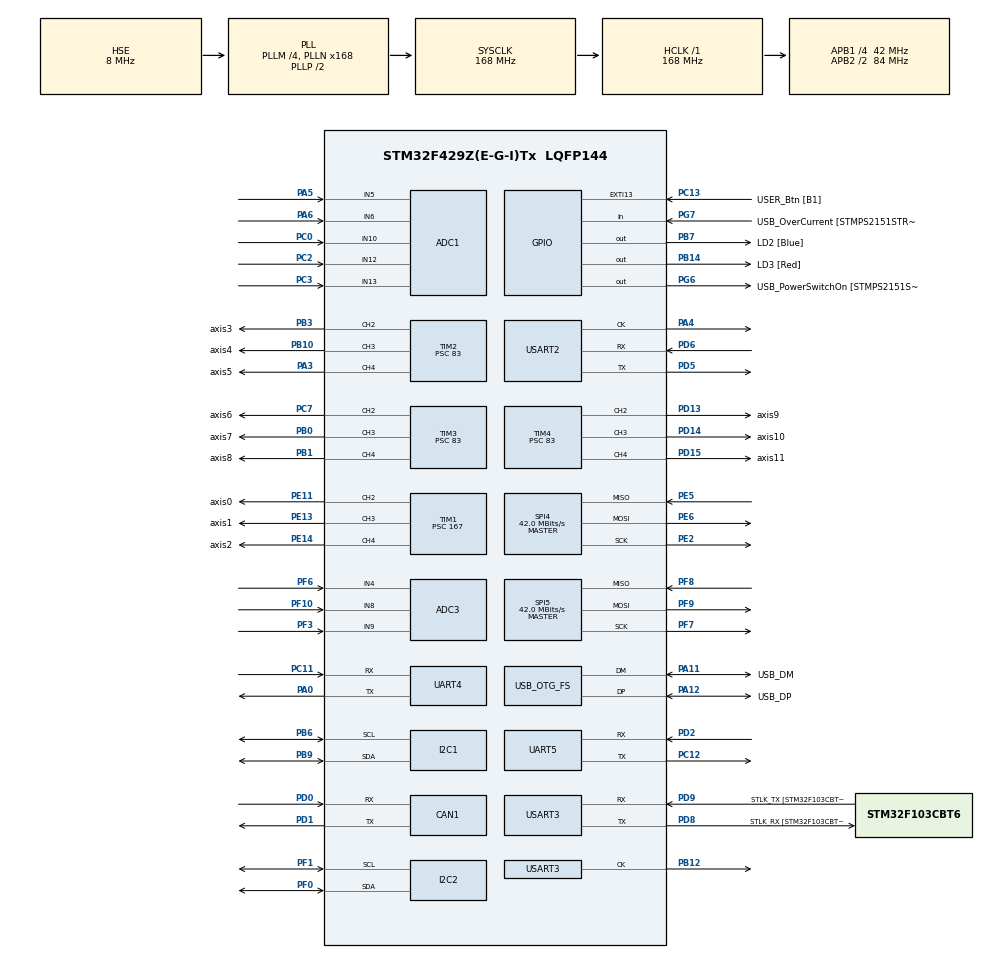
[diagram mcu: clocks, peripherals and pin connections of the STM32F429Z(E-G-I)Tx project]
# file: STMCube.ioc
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ADC1.Channel-0\#ChannelRegularConversion=ADC_CHANNEL_10
ADC1.NbrOfConversionFlag=1
ADC1.Rank-0\#ChannelRegularConversion=1
ADC1.SamplingTime-0\#ChannelRegularConversion=ADC_SAMPLETIME_3CYCLES
ADC1.master=1
ADC2.Channel-0\#ChannelRegularConversion=ADC_CHANNEL_10
ADC2.NbrOfConversionFlag=1
ADC2.Rank-0\#ChannelRegularConversion=1
ADC2.SamplingTime-0\#ChannelRegularConversion=ADC_SAMPLETIME_3CYCLES
ADC3.Channel-0\#ChannelRegularConversion=ADC_CHANNEL_4
ADC3.NbrOfConversionFlag=1
ADC3.Rank-0\#ChannelRegularConversion=1
ADC3.SamplingTime-0\#ChannelRegularConversion=ADC_SAMPLETIME_3CYCLES
CAN1.BS1=CAN_BS1_1TQ
CAN1.BS2=CAN_BS2_1TQ
CAN1.CalculateTimeBit=1142
CAN1.CalculateTimeQuantum=380.95238095238096
Dma.Request0=TIM1_CH1
Dma.Request1=TIM2_CH1
Dma.Request2=TIM3_CH1/TRIG
Dma.Request3=TIM4_CH1
Dma.TIM1_CH1.0.Direction=DMA_MEMORY_TO_PERIPH
Dma.TIM1_CH1.0.FIFOMode=DMA_FIFOMODE_DISABLE
Dma.TIM1_CH1.0.Instance=DMA2_Stream1
Dma.TIM1_CH1.0.MemDataAlignment=DMA_MDATAALIGN_HALFWORD
Dma.TIM1_CH1.0.MemInc=DMA_MINC_ENABLE
Dma.TIM1_CH1.0.Mode=DMA_NORMAL
Dma.TIM1_CH1.0.PeriphDataAlignment=DMA_PDATAALIGN_HALFWORD
Dma.TIM1_CH1.0.PeriphInc=DMA_PINC_DISABLE
Dma.TIM1_CH1.0.Priority=DMA_PRIORITY_HIGH
Dma.TIM2_CH1.1.Direction=DMA_MEMORY_TO_PERIPH
Dma.TIM2_CH1.1.FIFOMode=DMA_FIFOMODE_DISABLE
Dma.TIM2_CH1.1.Instance=DMA1_Stream5
Dma.TIM2_CH1.1.MemDataAlignment=DMA_MDATAALIGN_WORD
Dma.TIM2_CH1.1.MemInc=DMA_MINC_ENABLE
Dma.TIM2_CH1.1.Mode=DMA_NORMAL
Dma.TIM2_CH1.1.PeriphDataAlignment=DMA_PDATAALIGN_WORD
Dma.TIM2_CH1.1.PeriphInc=DMA_PINC_DISABLE
Dma.TIM2_CH1.1.Priority=DMA_PRIORITY_HIGH
Dma.TIM3_CH1/TRIG.2.Direction=DMA_MEMORY_TO_PERIPH
Dma.TIM3_CH1/TRIG.2.FIFOMode=DMA_FIFOMODE_DISABLE
Dma.TIM3_CH1/TRIG.2.Instance=DMA1_Stream4
Dma.TIM3_CH1/TRIG.2.MemDataAlignment=DMA_MDATAALIGN_HALFWORD
Dma.TIM3_CH1/TRIG.2.MemInc=DMA_MINC_ENABLE
Dma.TIM3_CH1/TRIG.2.Mode=DMA_NORMAL
Dma.TIM3_CH1/TRIG.2.PeriphDataAlignment=DMA_PDATAALIGN_HALFWORD
Dma.TIM3_CH1/TRIG.2.PeriphInc=DMA_PINC_DISABLE
Dma.TIM3_CH1/TRIG.2.Priority=DMA_PRIORITY_HIGH
Dma.TIM4_CH1.3.Direction=DMA_MEMORY_TO_PERIPH
Dma.TIM4_CH1.3.FIFOMode=DMA_FIFOMODE_DISABLE
Dma.TIM4_CH1.3.Instance=DMA1_Stream0
Dma.TIM4_CH1.3.MemDataAlignment=DMA_MDATAALIGN_HALFWORD
Dma.TIM4_CH1.3.MemInc=DMA_MINC_ENABLE
Dma.TIM4_CH1.3.Mode=DMA_NORMAL
Dma.TIM4_CH1.3.PeriphDataAlignment=DMA_PDATAALIGN_HALFWORD
Dma.TIM4_CH1.3.PeriphInc=DMA_PINC_DISABLE
Dma.TIM4_CH1.3.Priority=DMA_PRIORITY_HIGH
FREERTOS.Tasks01=defaultTask,0,128,StartDefaultTask,Default,NULL
FREERTOS.configENABLE_BACKWARD_COMPATIBILITY=0
FREERTOS.configTOTAL_HEAP_SIZE=65536
FREERTOS.configUSE_COUNTING_SEMAPHORES=1
Mcu.Family=STM32F4
Mcu.Name=STM32F429Z(E-G-I)Tx
Mcu.Package=LQFP144
NVIC.DMA1_Stream0_IRQn=true\:5\:0\:false\:false\:true\:true\:false
NVIC.DMA1_Stream4_IRQn=true\:5\:0\:false\:false\:true\:true\:false
NVIC.DMA1_Stream5_IRQn=true\:5\:0\:false\:false\:true\:true\:false
NVIC.DMA2_Stream1_IRQn=true\:5\:0\:false\:false\:true\:true\:false
NVIC.OTG_FS_IRQn=true\:5\:0\:false\:false\:true\:true\:false
NVIC.PriorityGroup=NVIC_PRIORITYGROUP_4
NVIC.TIM8_UP_TIM13_IRQn=true\:0\:0\:false\:false\:true\:false\:false
NVIC.TimeBase=TIM8_UP_TIM13_IRQn
NVIC.TimeBaseIP=TIM13
PA0/WKUP.Mode=Asynchronous
PA0/WKUP.Signal=UART4_TX
PA1.GPIO_Label=RMII_REF_CLK [LAN8742A-CZ-TR_REFCLK0]
PA1.Signal=ETH_REF_CLK
PA10.GPIO_Label=USB_ID
PA10.Signal=USB_OTG_FS_ID
PA11.GPIO_Label=USB_DM
PA11.Mode=Device_Only
PA11.Signal=USB_OTG_FS_DM
PA12.GPIO_Label=USB_DP
PA12.Mode=Device_Only
PA12.Signal=USB_OTG_FS_DP
PA13.GPIO_Label=TMS
PA13.Mode=Serial_Wire
PA13.Signal=SYS_JTMS-SWDIO
PA14.GPIO_Label=TCK
PA14.Mode=Serial_Wire
PA14.Signal=SYS_JTCK-SWCLK
PA2.GPIO_Label=RMII_MDIO [LAN8742A-CZ-TR_MDIO]
PA2.Signal=ETH_MDIO
PA3.GPIO_Label=axis5
PA3.GPIO_Speed=GPIO_SPEED_FREQ_VERY_HIGH
PA3.Signal=S_TIM2_CH4
PA4.Mode=Synchronous
PA4.Signal=USART2_CK
PA5.Signal=ADCx_IN5
PA6.Signal=ADCx_IN6
PA7.GPIO_Label=RMII_CRS_DV [LAN8742A-CZ-TR_CRS_DV]
PA7.Signal=ETH_CRS_DV
PA8.GPIO_Label=USB_SOF [TP1]
PA8.Signal=USB_OTG_FS_SOF
PA9.GPIO_Label=USB_VBUS
PA9.Signal=USB_OTG_FS_VBUS
PB0.GPIO_Label=axis7
PB0.GPIO_Speed=GPIO_SPEED_FREQ_VERY_HIGH
PB0.Signal=S_TIM3_CH3
PB1.GPIO_Label=axis8
PB1.GPIO_Speed=GPIO_SPEED_FREQ_VERY_HIGH
PB1.Signal=S_TIM3_CH4
PB10.GPIO_Label=axis4
PB10.GPIO_Speed=GPIO_SPEED_FREQ_VERY_HIGH
PB10.Signal=S_TIM2_CH3
PB12.Mode=Synchronous
PB12.Signal=USART3_CK
PB13.GPIO_Label=RMII_TXD1 [LAN8742A-CZ-TR_TXD1]
PB13.Signal=ETH_TXD1
PB14.GPIO_Label=LD3 [Red]
PB14.Signal=GPIO_Output
PB3.GPIO_Label=axis3
PB3.GPIO_Speed=GPIO_SPEED_FREQ_VERY_HIGH
PB3.Signal=S_TIM2_CH2
PB6.Mode=I2C
PB6.Signal=I2C1_SCL
PB7.GPIO_Label=LD2 [Blue]
PB7.Signal=GPIO_Output
PB9.Mode=I2C
PB9.Signal=I2C1_SDA
PC0.Signal=ADCx_IN10
PC1.GPIO_Label=RMII_MDC [LAN8742A-CZ-TR_MDC]
PC1.Signal=ETH_MDC
PC11.Mode=Asynchronous
PC11.Signal=UART4_RX
PC12.Mode=Asynchronous
PC12.Signal=UART5_TX
PC13.GPIO_Label=USER_Btn [B1]
PC13.Signal=GPXTI13
PC14/OSC32_IN.Mode=LSE-External-Oscillator
PC14/OSC32_IN.Signal=RCC_OSC32_IN
PC15/OSC32_OUT.Mode=LSE-External-Oscillator
PC15/OSC32_OUT.Signal=RCC_OSC32_OUT
PC2.Signal=ADCx_IN12
PC3.Signal=ADCx_IN13
PC4.GPIO_Label=RMII_RXD0 [LAN8742A-CZ-TR_RXD0]
PC4.Signal=ETH_RXD0
PC5.GPIO_Label=RMII_RXD1 [LAN8742A-CZ-TR_RXD1]
PC5.Signal=ETH_RXD1
PC7.GPIO_Label=axis6
PC7.GPIO_Speed=GPIO_SPEED_FREQ_VERY_HIGH
PC7.Signal=S_TIM3_CH2
PD0.Mode=Master
PD0.Signal=CAN1_RX
PD1.Mode=Master
PD1.Signal=CAN1_TX
PD13.GPIO_Label=axis9
PD13.GPIO_Speed=GPIO_SPEED_FREQ_VERY_HIGH
PD13.Signal=S_TIM4_CH2
PD14.GPIO_Label=axis10
PD14.GPIO_Speed=GPIO_SPEED_FREQ_VERY_HIGH
PD14.Signal=S_TIM4_CH3
PD15.GPIO_Label=axis11
PD15.GPIO_Speed=GPIO_SPEED_FREQ_VERY_HIGH
PD15.Signal=S_TIM4_CH4
PD2.Mode=Asynchronous
PD2.Signal=UART5_RX
PD5.Mode=Synchronous
PD5.Signal=USART2_TX
PD6.Mode=Synchronous
PD6.Signal=USART2_RX
PD8.GPIO_Label=STLK_RX [STM32F103CBT6_PA3]
PD8.Mode=Synchronous
PD8.Signal=USART3_TX
PD9.GPIO_Label=STLK_TX [STM32F103CBT6_PA2]
PD9.Mode=Synchronous
PD9.Signal=USART3_RX
PE11.GPIO_Label=axis0
PE11.GPIO_Speed=GPIO_SPEED_FREQ_VERY_HIGH
PE11.Signal=S_TIM1_CH2
PE13.GPIO_Label=axis1
PE13.GPIO_Speed=GPIO_SPEED_FREQ_VERY_HIGH
PE13.Signal=S_TIM1_CH3
PE14.GPIO_Label=axis2
PE14.GPIO_Speed=GPIO_SPEED_FREQ_VERY_HIGH
PE14.Signal=S_TIM1_CH4
PE2.Mode=Full_Duplex_Master
PE2.Signal=SPI4_SCK
PE5.Mode=Full_Duplex_Master
PE5.Signal=SPI4_MISO
PE6.Mode=Full_Duplex_Master
PE6.Signal=SPI4_MOSI
PF0.Mode=I2C
PF0.Signal=I2C2_SDA
PF1.Mode=I2C
PF1.Signal=I2C2_SCL
PF10.Mode=IN8
PF10.Signal=ADC3_IN8
PF3.Mode=IN9
PF3.Signal=ADC3_IN9
PF6.Mode=IN4
PF6.Signal=ADC3_IN4
PF7.Mode=Full_Duplex_Master
PF7.Signal=SPI5_SCK
PF8.Mode=Full_Duplex_Master
PF8.Signal=SPI5_MISO
PF9.Mode=Full_Duplex_Master
PF9.Signal=SPI5_MOSI
PG11.GPIO_Label=RMII_TX_EN [LAN8742A-CZ-TR_TXEN]
PG11.Signal=ETH_TX_EN
PG13.GPIO_Label=RMII_TXD0 [LAN8742A-CZ-TR_TXD0]
PG13.Signal=ETH_TXD0
PG6.GPIO_Label=USB_PowerSwitchOn [STMPS2151STR_EN]
PG6.Signal=GPIO_Output
PG7.GPIO_Label=USB_OverCurrent [STMPS2151STR_FAULT]
PG7.Signal=GPIO_Input
PH0/OSC_IN.GPIO_Label=MCO [STM32F103CBT6_PA8]
PH0/OSC_IN.Mode=HSE-External-Oscillator
PH0/OSC_IN.Signal=RCC_OSC_IN
PH1/OSC_OUT.Mode=HSE-External-Oscillator
PH1/OSC_OUT.Signal=RCC_OSC_OUT
ProjectManager.HeapSize=0x200
ProjectManager.StackSize=0x400
ProjectManager.TargetToolchain=SW4STM32
RCC.48MHZClocksFreq_Value=48000000
RCC.AHBFreq_Value=168000000
RCC.APB1CLKDivider=RCC_HCLK_DIV4
RCC.APB1Freq_Value=42000000
RCC.APB1TimFreq_Value=84000000
RCC.APB2CLKDivider=RCC_HCLK_DIV2
RCC.APB2Freq_Value=84000000
RCC.APB2TimFreq_Value=168000000
RCC.CortexFreq_Value=168000000
RCC.HCLKFreq_Value=168000000
RCC.HSE_VALUE=8000000
RCC.HSI_VALUE=16000000
RCC.PLLM=4
RCC.PLLMUL=RCC_PLL_MUL9
RCC.PLLN=168
RCC.PLLQ=7
RCC.PRESCALERUSB=RCC_USBCLKSOURCE_PLL_DIV1_5
RCC.SYSCLKFreq_VALUE=168000000
RCC.SYSCLKSource=RCC_SYSCLKSOURCE_PLLCLK
RCC.SYSCLKSourceVirtual=RCC_SYSCLKSOURCE_PLLCLK
RCC.USBFreq_Value=48000000
RCC.VCOOutputFreq_Value=336000000
SH.ADCx_IN10.0=ADC1_IN10,IN10
SH.ADCx_IN10.1=ADC2_IN10,IN10
SH.ADCx_IN10.2=ADC3_IN10,IN10
SH.ADCx_IN12.0=ADC1_IN12,IN12
SH.ADCx_IN12.1=ADC2_IN12,IN12
SH.ADCx_IN12.2=ADC3_IN12,IN12
SH.ADCx_IN13.0=ADC1_IN13,IN13
SH.ADCx_IN13.1=ADC2_IN13,IN13
SH.ADCx_IN13.2=ADC3_IN13,IN13
SH.ADCx_IN5.0=ADC1_IN5,IN5
SH.ADCx_IN5.1=ADC2_IN5,IN5
SH.ADCx_IN6.0=ADC1_IN6,IN6
SH.ADCx_IN6.1=ADC2_IN6,IN6
SH.S_TIM1_CH2.0=TIM1_CH2,Output Compare2 CH2
SH.S_TIM1_CH3.0=TIM1_CH3,Output Compare3 CH3
SH.S_TIM1_CH4.0=TIM1_CH4,Output Compare4 CH4
SH.S_TIM2_CH2.0=TIM2_CH2,Output Compare2 CH2
SH.S_TIM2_CH3.0=TIM2_CH3,Output Compare3 CH3
SH.S_TIM2_CH4.0=TIM2_CH4,Output Compare4 CH4
SH.S_TIM3_CH2.0=TIM3_CH2,Output Compare2 CH2
SH.S_TIM3_CH3.0=TIM3_CH3,Output Compare3 CH3
SH.S_TIM3_CH4.0=TIM3_CH4,Output Compare4 CH4
SH.S_TIM4_CH2.0=TIM4_CH2,Output Compare2 CH2
SH.S_TIM4_CH3.0=TIM4_CH3,Output Compare3 CH3
SH.S_TIM4_CH4.0=TIM4_CH4,Output Compare4 CH4
SPI4.BaudRatePrescaler=SPI_BAUDRATEPRESCALER_2
SPI4.CalculateBaudRate=42.0 MBits/s
SPI4.Direction=SPI_DIRECTION_2LINES
SPI4.Mode=SPI_MODE_MASTER
SPI4.VirtualType=VM_MASTER
SPI5.BaudRatePrescaler=SPI_BAUDRATEPRESCALER_2
SPI5.CalculateBaudRate=42.0 MBits/s
SPI5.Direction=SPI_DIRECTION_2LINES
SPI5.Mode=SPI_MODE_MASTER
SPI5.VirtualType=VM_MASTER
TIM1.Channel-Output\ Compare1\ No\ Output=TIM_CHANNEL_1
TIM1.Channel-Output\ Compare2\ CH2=TIM_CHANNEL_2
TIM1.Channel-Output\ Compare3\ CH3=TIM_CHANNEL_3
TIM1.Channel-Output\ Compare4\ CH4=TIM_CHANNEL_4
TIM1.Prescaler=167
TIM2.Channel-Output\ Compare1\ No\ Output=TIM_CHANNEL_1
TIM2.Channel-Output\ Compare2\ CH2=TIM_CHANNEL_2
TIM2.Channel-Output\ Compare3\ CH3=TIM_CHANNEL_3
TIM2.Channel-Output\ Compare4\ CH4=TIM_CHANNEL_4
TIM2.Prescaler=83
TIM3.Channel-Output\ Compare1\ No\ Output=TIM_CHANNEL_1
TIM3.Channel-Output\ Compare2\ CH2=TIM_CHANNEL_2
TIM3.Channel-Output\ Compare3\ CH3=TIM_CHANNEL_3
TIM3.Channel-Output\ Compare4\ CH4=TIM_CHANNEL_4
TIM3.Prescaler=83
TIM4.Channel-Output\ Compare1\ No\ Output=TIM_CHANNEL_1
TIM4.Channel-Output\ Compare2\ CH2=TIM_CHANNEL_2
TIM4.Channel-Output\ Compare3\ CH3=TIM_CHANNEL_3
TIM4.Channel-Output\ Compare4\ CH4=TIM_CHANNEL_4
TIM4.Prescaler=83
UART4.VirtualMode=Asynchronous
UART5.VirtualMode=Asynchronous
USART2.VirtualMode=VM_SYNC
USART3.VirtualMode=VM_SYNC
USB_DEVICE.CLASS_NAME_FS=CDC
USB_DEVICE.USBD_MAX_NUM_CONFIGURATION-CDC_FS=1
USB_DEVICE.USBD_MAX_NUM_INTERFACES-CDC_FS=1
USB_DEVICE.USBD_MAX_STR_DESC_SIZ-CDC_FS=48
USB_DEVICE.VirtualMode-CDC_FS=Cdc
USB_DEVICE.VirtualModeFS=Cdc_FS
USB_OTG_FS.VirtualMode=Device_Only
VP_ADC1_TempSens_Input.Mode=IN-TempSens
VP_CRC_VS_CRC.Mode=CRC_Activate
VP_FREERTOS_VS_ENABLE.Mode=Enabled
VP_SYS_VS_tim13.Mode=TIM13
VP_TIM1_VS_ClockSourceINT.Mode=Internal
VP_TIM1_VS_no_output1.Mode=Output Compare1 No Output
VP_TIM2_VS_ClockSourceINT.Mode=Internal
VP_TIM2_VS_no_output1.Mode=Output Compare1 No Output
VP_TIM3_VS_ClockSourceINT.Mode=Internal
VP_TIM3_VS_no_output1.Mode=Output Compare1 No Output
VP_TIM4_VS_ClockSourceINT.Mode=Internal
VP_TIM4_VS_no_output1.Mode=Output Compare1 No Output
VP_USB_DEVICE_VS_USB_DEVICE_CDC_FS.Mode=CDC_FS
board=NUCLEO-F429ZI

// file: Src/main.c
/**
  ******************************************************************************
  * File Name          : main.c
  * Description        : Main program body
  ******************************************************************************
  * This notice applies to any and all portions of this file
  * that are not between comment pairs USER CODE BEGIN and
  * USER CODE END. Other portions of this file, whether
  * inserted by the user or by software development tools
  * are owned by their respective copyright owners.
  *
  * Copyright (c) 2018 STMicroelectronics International N.V.
  * All rights reserved.
  *
  * Redistribution and use in source and binary forms, with or without
  * modification, are permitted, provided that the following conditions are met:
  *
  * 1. Redistribution of source code must retain the above copyright notice,
  *    this list of conditions and the following disclaimer.
  * 2. Redistributions in binary form must reproduce the above copyright notice,
  *    this list of conditions and the following disclaimer in the documentation
  *    and/or other materials provided with the distribution.
  * 3. Neither the name of STMicroelectronics nor the names of other
  *    contributors to this software may be used to endorse or promote products
  *    derived from this software without specific written permission.
  * 4. This software, including modifications and/or derivative works of this
  *    software, must execute solely and exclusively on microcontroller or
  *    microprocessor devices manufactured by or for STMicroelectronics.
  * 5. Redistribution and use of this software other than as permitted under
  *    this license is void and will automatically terminate your rights under
  *    this license.
  *
  * THIS SOFTWARE IS PROVIDED BY STMICROELECTRONICS AND CONTRIBUTORS "AS IS"
  * AND ANY EXPRESS, IMPLIED OR STATUTORY WARRANTIES, INCLUDING, BUT NOT
  * LIMITED TO, THE IMPLIED WARRANTIES OF MERCHANTABILITY, FITNESS FOR A
  * PARTICULAR PURPOSE AND NON-INFRINGEMENT OF THIRD PARTY INTELLECTUAL PROPERTY
  * RIGHTS ARE DISCLAIMED TO THE FULLEST EXTENT PERMITTED BY LAW. IN NO EVENT
  * SHALL STMICROELECTRONICS OR CONTRIBUTORS BE LIABLE FOR ANY DIRECT, INDIRECT,
  * INCIDENTAL, SPECIAL, EXEMPLARY, OR CONSEQUENTIAL DAMAGES (INCLUDING, BUT NOT
  * LIMITED TO, PROCUREMENT OF SUBSTITUTE GOODS OR SERVICES; LOSS OF USE, DATA,
  * OR PROFITS; OR BUSINESS INTERRUPTION) HOWEVER CAUSED AND ON ANY THEORY OF
  * LIABILITY, WHETHER IN CONTRACT, STRICT LIABILITY, OR TORT (INCLUDING
  * NEGLIGENCE OR OTHERWISE) ARISING IN ANY WAY OUT OF THE USE OF THIS SOFTWARE,
  * EVEN IF ADVISED OF THE POSSIBILITY OF SUCH DAMAGE.
  *
  ******************************************************************************
  */
#include "main.h"
#include "stm32f4xx_hal.h"
#include "cmsis_os.h"
#include "adc.h"
#include "can.h"
#include "crc.h"
#include "dma.h"
#include "i2c.h"
#include "spi.h"
#include "tim.h"
#include "usart.h"
#include "usb_device.h"
#include "gpio.h"

/* USER CODE BEGIN PV */
/* Private variables ---------------------------------------------------------*/

/* USER CODE END PV */

void SystemClock_Config(void);
void MX_FREERTOS_Init(void);

/* USER CODE BEGIN PFP */
/* Private function prototypes -----------------------------------------------*/

/* USER CODE END PFP */

int main(void)
{

  /* MCU Configuration----------------------------------------------------------*/

  /* Reset of all peripherals, Initializes the Flash interface and the Systick. */
  HAL_Init();

  /* Configure the system clock */
  SystemClock_Config();

  /* Initialize all configured peripherals */
  MX_GPIO_Init();
  MX_DMA_Init();
  MX_CAN1_Init();
  MX_I2C2_Init();
  MX_TIM2_Init();
  MX_TIM3_Init();
  MX_TIM4_Init();
  MX_TIM1_Init();
  MX_I2C1_Init();
  MX_UART4_Init();
  MX_UART5_Init();
  MX_USART2_Init();
  MX_USART3_Init();
  MX_CRC_Init();
  MX_ADC1_Init();
  MX_ADC2_Init();
  MX_SPI4_Init();
  MX_SPI5_Init();
  MX_ADC3_Init();

  /* Call init function for freertos objects (in freertos.c) */
  MX_FREERTOS_Init();

  /* Start scheduler */
  osKernelStart();

  /* We should never get here as control is now taken by the scheduler */

  /* Infinite loop */
  while (1)
  {

  }

}

/** System Clock Configuration
*/
void SystemClock_Config(void)
{

  RCC_OscInitTypeDef RCC_OscInitStruct;
  RCC_ClkInitTypeDef RCC_ClkInitStruct;

    /**Configure the main internal regulator output voltage
    */
  __HAL_RCC_PWR_CLK_ENABLE();

  __HAL_PWR_VOLTAGESCALING_CONFIG(PWR_REGULATOR_VOLTAGE_SCALE1);

    /**Initializes the CPU, AHB and APB busses clocks
    */
  RCC_OscInitStruct.OscillatorType = RCC_OSCILLATORTYPE_HSE;
  RCC_OscInitStruct.HSEState = RCC_HSE_ON;
  RCC_OscInitStruct.PLL.PLLState = RCC_PLL_ON;
  RCC_OscInitStruct.PLL.PLLSource = RCC_PLLSOURCE_HSE;
  RCC_OscInitStruct.PLL.PLLM = 4;
  RCC_OscInitStruct.PLL.PLLN = 168;
  RCC_OscInitStruct.PLL.PLLP = RCC_PLLP_DIV2;
  RCC_OscInitStruct.PLL.PLLQ = 7;
  if (HAL_RCC_OscConfig(&RCC_OscInitStruct) != HAL_OK)
  {
    _Error_Handler(__FILE__, __LINE__);
  }

    /**Initializes the CPU, AHB and APB busses clocks
    */
  RCC_ClkInitStruct.ClockType = RCC_CLOCKTYPE_HCLK|RCC_CLOCKTYPE_SYSCLK
                              |RCC_CLOCKTYPE_PCLK1|RCC_CLOCKTYPE_PCLK2;
  RCC_ClkInitStruct.SYSCLKSource = RCC_SYSCLKSOURCE_PLLCLK;
  RCC_ClkInitStruct.AHBCLKDivider = RCC_SYSCLK_DIV1;
  RCC_ClkInitStruct.APB1CLKDivider = RCC_HCLK_DIV4;
  RCC_ClkInitStruct.APB2CLKDivider = RCC_HCLK_DIV2;

  if (HAL_RCC_ClockConfig(&RCC_ClkInitStruct, FLASH_LATENCY_5) != HAL_OK)
  {
    _Error_Handler(__FILE__, __LINE__);
  }

    /**Configure the Systick interrupt time
    */
  HAL_SYSTICK_Config(HAL_RCC_GetHCLKFreq()/1000);

    /**Configure the Systick
    */
  HAL_SYSTICK_CLKSourceConfig(SYSTICK_CLKSOURCE_HCLK);

  /* SysTick_IRQn interrupt configuration */
  HAL_NVIC_SetPriority(SysTick_IRQn, 15, 0);
}

void HAL_TIM_PeriodElapsedCallback(TIM_HandleTypeDef *htim)
{
  if (htim->Instance == TIM13) {
    HAL_IncTick();
  }
}

void _Error_Handler(char * file, int line)
{
  while(1)
  {
  }
}

/************************ (C) COPYRIGHT STMicroelectronics *****END OF FILE****/

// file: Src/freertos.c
/**
  ******************************************************************************
  * File Name          : freertos.c
  * Description        : Code for freertos applications
  ******************************************************************************
  * This notice applies to any and all portions of this file
  * that are not between comment pairs USER CODE BEGIN and
  * USER CODE END. Other portions of this file, whether
  * inserted by the user or by software development tools
  * are owned by their respective copyright owners.
  *
  * Copyright (c) 2018 STMicroelectronics International N.V.
  * All rights reserved.
  *
  * Redistribution and use in source and binary forms, with or without
  * modification, are permitted, provided that the following conditions are met:
  *
  * 1. Redistribution of source code must retain the above copyright notice,
  *    this list of conditions and the following disclaimer.
  * 2. Redistributions in binary form must reproduce the above copyright notice,
  *    this list of conditions and the following disclaimer in the documentation
  *    and/or other materials provided with the distribution.
  * 3. Neither the name of STMicroelectronics nor the names of other
  *    contributors to this software may be used to endorse or promote products
  *    derived from this software without specific written permission.
  * 4. This software, including modifications and/or derivative works of this
  *    software, must execute solely and exclusively on microcontroller or
  *    microprocessor devices manufactured by or for STMicroelectronics.
  * 5. Redistribution and use of this software other than as permitted under
  *    this license is void and will automatically terminate your rights under
  *    this license.
  *
  * THIS SOFTWARE IS PROVIDED BY STMICROELECTRONICS AND CONTRIBUTORS "AS IS"
  * AND ANY EXPRESS, IMPLIED OR STATUTORY WARRANTIES, INCLUDING, BUT NOT
  * LIMITED TO, THE IMPLIED WARRANTIES OF MERCHANTABILITY, FITNESS FOR A
  * PARTICULAR PURPOSE AND NON-INFRINGEMENT OF THIRD PARTY INTELLECTUAL PROPERTY
  * RIGHTS ARE DISCLAIMED TO THE FULLEST EXTENT PERMITTED BY LAW. IN NO EVENT
  * SHALL STMICROELECTRONICS OR CONTRIBUTORS BE LIABLE FOR ANY DIRECT, INDIRECT,
  * INCIDENTAL, SPECIAL, EXEMPLARY, OR CONSEQUENTIAL DAMAGES (INCLUDING, BUT NOT
  * LIMITED TO, PROCUREMENT OF SUBSTITUTE GOODS OR SERVICES; LOSS OF USE, DATA,
  * OR PROFITS; OR BUSINESS INTERRUPTION) HOWEVER CAUSED AND ON ANY THEORY OF
  * LIABILITY, WHETHER IN CONTRACT, STRICT LIABILITY, OR TORT (INCLUDING
  * NEGLIGENCE OR OTHERWISE) ARISING IN ANY WAY OUT OF THE USE OF THIS SOFTWARE,
  * EVEN IF ADVISED OF THE POSSIBILITY OF SUCH DAMAGE.
  *
  ******************************************************************************
  */

#include "FreeRTOS.h"
#include "task.h"
#include "cmsis_os.h"

osThreadId defaultTaskHandle;

void StartDefaultTask(void const * argument);

extern void MX_USB_DEVICE_Init(void);
void MX_FREERTOS_Init(void); /* (MISRA C 2004 rule 8.1) */

/* USER CODE BEGIN FunctionPrototypes */

extern void start_main_task(void);

/* USER CODE END FunctionPrototypes */

/* Hook prototypes */

/* Init FreeRTOS */

void MX_FREERTOS_Init(void) {

  /* Create the thread(s) */
  /* definition and creation of defaultTask */
  osThreadDef(defaultTask, StartDefaultTask, osPriorityNormal, 0, 128);
  defaultTaskHandle = osThreadCreate(osThread(defaultTask), NULL);

}

/* StartDefaultTask function */
void StartDefaultTask(void const * argument)
{
  /* init code for USB_DEVICE */
  MX_USB_DEVICE_Init();

  /* USER CODE BEGIN StartDefaultTask */
  start_main_task();
  osThreadTerminate(defaultTaskHandle);
  while(1){
    osThreadYield();
  }

  /* USER CODE END StartDefaultTask */
}

/************************ (C) COPYRIGHT STMicroelectronics *****END OF FILE****/
